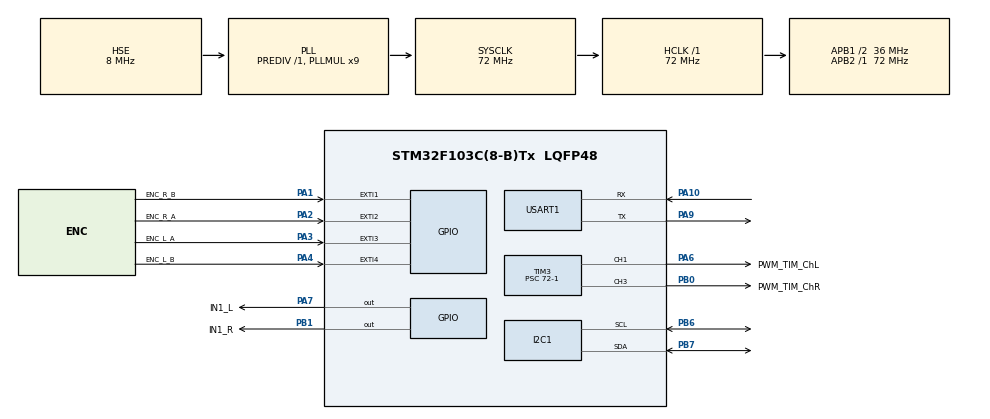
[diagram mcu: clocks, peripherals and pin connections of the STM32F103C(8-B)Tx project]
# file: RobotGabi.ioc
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Mcu.Family=STM32F1
Mcu.Name=STM32F103C(8-B)Tx
Mcu.Package=LQFP48
Mcu.UserConstants=PWM_TIM,$$_TIM3_IP_HANDLE_$$;UART_BT_old,$$_USART2_IP_HANDLE_$$;UART_BT,$$_USART1_IP_HANDLE_$$;I2C_SENSORS,$$_I2C1_IP_HANDLE_$$;PID_Timer,$$_TIM4_IP_HANDLE_$$
NVIC.EXTI1_IRQn=true\:0\:0\:false\:false\:true\:true\:true\:true
NVIC.EXTI2_IRQn=true\:0\:0\:false\:false\:true\:true\:true\:true
NVIC.EXTI3_IRQn=true\:0\:0\:false\:false\:true\:true\:true\:true
NVIC.EXTI4_IRQn=true\:0\:0\:false\:false\:true\:true\:true\:true
NVIC.PriorityGroup=NVIC_PRIORITYGROUP_4
NVIC.TIM4_IRQn=true\:1\:0\:true\:false\:true\:true\:true\:true
PA1.GPIO_Label=ENC_R_B
PA1.GPIO_ModeDefaultEXTI=GPIO_MODE_IT_RISING_FALLING
PA1.Signal=GPXTI1
PA10.Mode=Asynchronous
PA10.Signal=USART1_RX
PA13.Mode=Serial_Wire
PA13.Signal=SYS_JTMS-SWDIO
PA14.Mode=Serial_Wire
PA14.Signal=SYS_JTCK-SWCLK
PA2.GPIO_Label=ENC_R_A
PA2.GPIO_ModeDefaultEXTI=GPIO_MODE_IT_RISING_FALLING
PA2.Signal=GPXTI2
PA3.GPIO_Label=ENC_L_A
PA3.GPIO_ModeDefaultEXTI=GPIO_MODE_IT_RISING_FALLING
PA3.Signal=GPXTI3
PA4.GPIO_Label=ENC_L_B
PA4.GPIO_ModeDefaultEXTI=GPIO_MODE_IT_RISING_FALLING
PA4.Signal=GPXTI4
PA6.GPIO_Label=PWM_TIM_ChL
PA6.Signal=S_TIM3_CH1
PA7.GPIO_Label=IN1_L
PA7.Signal=GPIO_Output
PA9.Mode=Asynchronous
PA9.Signal=USART1_TX
PB0.GPIO_Label=PWM_TIM_ChR
PB0.Signal=S_TIM3_CH3
PB1.GPIO_Label=IN1_R
PB1.Signal=GPIO_Output
PB6.Mode=I2C
PB6.Signal=I2C1_SCL
PB7.Mode=I2C
PB7.Signal=I2C1_SDA
PD0-OSC_IN.Mode=HSE-External-Oscillator
PD0-OSC_IN.Signal=RCC_OSC_IN
PD1-OSC_OUT.Mode=HSE-External-Oscillator
PD1-OSC_OUT.Signal=RCC_OSC_OUT
ProjectManager.HeapSize=0x200
ProjectManager.StackSize=0x400
ProjectManager.TargetToolchain=STM32CubeIDE
RCC.AHBFreq_Value=72000000
RCC.APB1CLKDivider=RCC_HCLK_DIV2
RCC.APB1Freq_Value=36000000
RCC.APB1TimFreq_Value=72000000
RCC.APB2Freq_Value=72000000
RCC.APB2TimFreq_Value=72000000
RCC.HCLKFreq_Value=72000000
RCC.PLLMUL=RCC_PLL_MUL9
RCC.PLLSourceVirtual=RCC_PLLSOURCE_HSE
RCC.SYSCLKFreq_VALUE=72000000
RCC.SYSCLKSource=RCC_SYSCLKSOURCE_PLLCLK
RCC.USBFreq_Value=72000000
SH.S_TIM3_CH1.0=TIM3_CH1,PWM Generation1 CH1
SH.S_TIM3_CH3.0=TIM3_CH3,PWM Generation3 CH3
TIM3.Channel-PWM\ Generation1\ CH1=TIM_CHANNEL_1
TIM3.Channel-PWM\ Generation3\ CH3=TIM_CHANNEL_3
TIM3.Period=1000-1
TIM3.Prescaler=72-1
TIM4.Period=10000-1
TIM4.Prescaler=72-1
USART1.VirtualMode=VM_ASYNC
VP_TIM3_VS_ClockSourceINT.Mode=Internal
VP_TIM4_VS_ClockSourceINT.Mode=Internal
board=custom

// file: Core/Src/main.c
/* USER CODE BEGIN Header */
/**
  ******************************************************************************
  * @file           : main.c
  * @brief          : Main program body
  ******************************************************************************
  * @attention
  *
  * Copyright (c) 2024 STMicroelectronics.
  * All rights reserved.
  *
  * This software is licensed under terms that can be found in the LICENSE file
  * in the root directory of this software component.
  * If no LICENSE file comes with this software, it is provided AS-IS.
  *
  ******************************************************************************
  */
/* USER CODE END Header */
#include "main.h"
#include "i2c.h"
#include "tim.h"
#include "usart.h"
#include "gpio.h"

/* USER CODE BEGIN Includes */
#include "main_cpp.h"
#include <stdio.h>
#include "main_cpp.h"

/* USER CODE END Includes */

void SystemClock_Config(void);

int main(void)
{

  /* MCU Configuration--------------------------------------------------------*/

  /* Reset of all peripherals, Initializes the Flash interface and the Systick. */
  HAL_Init();

  /* Configure the system clock */
  SystemClock_Config();

  /* Initialize all configured peripherals */
  MX_GPIO_Init();
  MX_I2C1_Init();
  MX_TIM3_Init();
  MX_TIM4_Init();
  MX_USART1_UART_Init();

  /* Infinite loop */
  /* USER CODE BEGIN WHILE */

  #ifdef DEBUG
  // Enable cycle counter to be able measure clock ticks:
  CoreDebug->DEMCR |= CoreDebug_DEMCR_TRCENA_Msk;
  DWT->CYCCNT = 0;
  DWT->CTRL |= DWT_CTRL_CYCCNTENA_Msk;
  #endif

  // Call to the "actual" main func (workaraound to use C++ with code completion tool):
  main_cpp();

  while (1)
  {
	  // VL53L0X_PerformSingleRangingMeasurement(Dev, &RangingData);

	  // if(RangingData.RangeStatus == 0)
	  // {
		//   MessageLen = sprintf((char*)Message, "Measured distance: %i\n\r", RangingData.RangeMilliMeter);
		//   HAL_UART_Transmit(&huart1, Message, MessageLen, 100);
	  // }
    /* USER CODE END WHILE */

  }
}

void SystemClock_Config(void)
{
  RCC_OscInitTypeDef RCC_OscInitStruct = {0};
  RCC_ClkInitTypeDef RCC_ClkInitStruct = {0};

  /** Initializes the RCC Oscillators according to the specified parameters
  * in the RCC_OscInitTypeDef structure.
  */
  RCC_OscInitStruct.OscillatorType = RCC_OSCILLATORTYPE_HSE;
  RCC_OscInitStruct.HSEState = RCC_HSE_ON;
  RCC_OscInitStruct.HSEPredivValue = RCC_HSE_PREDIV_DIV1;
  RCC_OscInitStruct.HSIState = RCC_HSI_ON;
  RCC_OscInitStruct.PLL.PLLState = RCC_PLL_ON;
  RCC_OscInitStruct.PLL.PLLSource = RCC_PLLSOURCE_HSE;
  RCC_OscInitStruct.PLL.PLLMUL = RCC_PLL_MUL9;
  if (HAL_RCC_OscConfig(&RCC_OscInitStruct) != HAL_OK)
  {
    Error_Handler();
  }

  /** Initializes the CPU, AHB and APB buses clocks
  */
  RCC_ClkInitStruct.ClockType = RCC_CLOCKTYPE_HCLK|RCC_CLOCKTYPE_SYSCLK
                              |RCC_CLOCKTYPE_PCLK1|RCC_CLOCKTYPE_PCLK2;
  RCC_ClkInitStruct.SYSCLKSource = RCC_SYSCLKSOURCE_PLLCLK;
  RCC_ClkInitStruct.AHBCLKDivider = RCC_SYSCLK_DIV1;
  RCC_ClkInitStruct.APB1CLKDivider = RCC_HCLK_DIV2;
  RCC_ClkInitStruct.APB2CLKDivider = RCC_HCLK_DIV1;

  if (HAL_RCC_ClockConfig(&RCC_ClkInitStruct, FLASH_LATENCY_2) != HAL_OK)
  {
    Error_Handler();
  }
}

void Error_Handler(void)
{
  __disable_irq();
  while (1)
  {
  }
}
